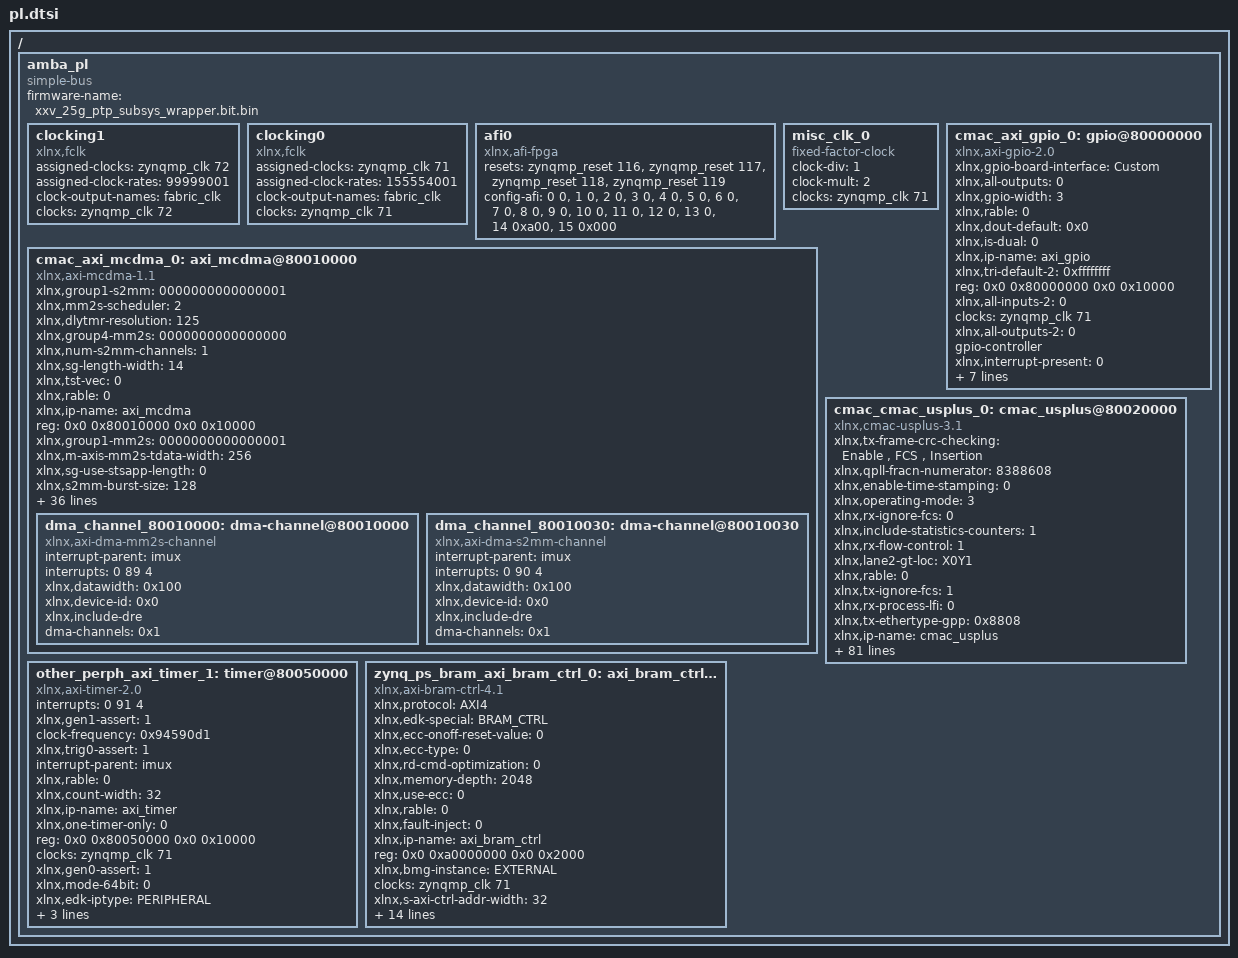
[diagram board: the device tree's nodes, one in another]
/ {
	amba_pl: amba_pl {
		ranges;
		compatible = "simple-bus";
		#address-cells = <2>;
		#size-cells = <2>;
		firmware-name = "xxv_25g_ptp_subsys_wrapper.bit.bin";
		clocking1: clocking1 {
			compatible = "xlnx,fclk";
			status = "okay";
			assigned-clocks = <&zynqmp_clk 72>;
			assigned-clock-rates = <99999001>;
			#clock-cells = <0>;
			clock-output-names = "fabric_clk";
			clocks = <&zynqmp_clk 72>;
		};
		clocking0: clocking0 {
			compatible = "xlnx,fclk";
			status = "okay";
			assigned-clocks = <&zynqmp_clk 71>;
			assigned-clock-rates = <155554001>;
			#clock-cells = <0>;
			clock-output-names = "fabric_clk";
			clocks = <&zynqmp_clk 71>;
		};
		afi0: afi0 {
			status = "okay";
			compatible = "xlnx,afi-fpga";
			resets = <&zynqmp_reset 116>, <&zynqmp_reset 117>, <&zynqmp_reset 118>, <&zynqmp_reset 119>;
			config-afi = < 0 0>, <1 0>, <2 0>, <3 0>, <4 0>, <5 0>, <6 0>, <7 0>, <8 0>, <9 0>, <10 0>, <11 0>, <12 0>, <13 0>, <14 0xa00>, <15 0x000>;
		};
		misc_clk_0: misc_clk_0 {
			clock-div = <1>;
			compatible = "fixed-factor-clock";
			clock-mult = <2>;
			clocks = <&zynqmp_clk 71>;
			#clock-cells = <0>;
		};
		cmac_axi_gpio_0: gpio@80000000 {
			xlnx,gpio-board-interface = "Custom";
			compatible = "xlnx,axi-gpio-2.0" , "xlnx,xps-gpio-1.00.a";
			xlnx,all-outputs = <0>;
			#gpio-cells = <2>;
			xlnx,gpio-width = <3>;
			xlnx,rable = <0>;
			xlnx,dout-default = <0x0>;
			xlnx,is-dual = <0>;
			xlnx,ip-name = "axi_gpio";
			xlnx,tri-default-2 = <0xffffffff>;
			reg = <0x0 0x80000000 0x0 0x10000>;
			xlnx,all-inputs-2 = <0>;
			clocks = <&zynqmp_clk 71>;
			xlnx,all-outputs-2 = <0>;
			gpio-controller;
			xlnx,interrupt-present = <0>;
			xlnx,gpio2-board-interface = "Custom";
			xlnx,edk-iptype = "PERIPHERAL";
			xlnx,dout-default-2 = <0x0>;
			status = "okay";
			xlnx,gpio2-width = <32>;
			clock-names = "s_axi_aclk";
			xlnx,tri-default = <0xffffffff>;
			xlnx,name = "cmac_axi_gpio_0";
			xlnx,all-inputs = <1>;
		};
		cmac_axi_mcdma_0: axi_mcdma@80010000 {
			xlnx,group1-s2mm = <0000000000000001>;
			xlnx,mm2s-scheduler = <2>;
			xlnx,dlytmr-resolution = <125>;
			xlnx,group4-mm2s = <0000000000000000>;
			xlnx,num-s2mm-channels = <1>;
			xlnx,sg-length-width = <14>;
			xlnx,tst-vec = <0>;
			xlnx,rable = <0>;
			xlnx,ip-name = "axi_mcdma";
			reg = <0x0 0x80010000 0x0 0x10000>;
			xlnx,group1-mm2s = <0000000000000001>;
			xlnx,m-axis-mm2s-tdata-width = <256>;
			xlnx,sg-use-stsapp-length = <0>;
			xlnx,s2mm-burst-size = <128>;
			xlnx,num-mm2s-channels = <1>;
			xlnx,group6-s2mm = <0000000000000000>;
			xlnx,enable-single-intr = <0>;
			interrupt-names = "mm2s_ch1_introut" , "s2mm_ch1_introut";
			xlnx,enable-multi-intr = <1>;
			compatible = "xlnx,axi-mcdma-1.1" , "xlnx,axi-mcdma-1.00.a";
			xlnx,group3-s2mm = <0000000000000000>;
			xlnx,mm2s-burst-size = <128>;
			interrupt-parent = <&imux>;
			xlnx,group6-mm2s = <0000000000000000>;
			xlnx,include-s2mm-dre = <1>;
			xlnx,group3-mm2s = <0000000000000000>;
			xlnx,m-axi-s2mm-data-width = <256>;
			status = "okay";
			xlnx,include-mm2s-dre = <1>;
			xlnx,name = "cmac_axi_mcdma_0";
			interrupts = < 0 89 4 0 90 4 >;
			xlnx,m-axi-mm2s-data-width = <256>;
			xlnx,group5-s2mm = <0000000000000000>;
			xlnx,include-s2mm-sf = <1>;
			xlnx,addr-width = <32>;
			xlnx,include-s2mm = <1>;
			xlnx,single-interface = <0>;
			clocks = <&misc_clk_0>, <&misc_clk_0>, <&zynqmp_clk 71>, <&zynqmp_clk 71>;
			xlnx,s-axis-s2mm-tdata-width = <256>;
			xlnx,addrwidth = /bits/ 8 <0x20>;
			xlnx,group2-s2mm = <0000000000000000>;
			xlnx,include-dre;
			xlnx,edk-iptype = "PERIPHERAL";
			xlnx,group5-mm2s = <0000000000000000>;
			xlnx,include-mm2s-sf = <1>;
			clock-names = "m_axi_mm2s_aclk" , "m_axi_s2mm_aclk" , "m_axi_sg_aclk" , "s_axi_lite_aclk";
			xlnx,include-mm2s = <1>;
			xlnx,s2mm-data-width = <0x100>;
			xlnx,group2-mm2s = <0000000000000000>;
			xlnx,prmry-is-aclk-async = <1>;
			#dma-cells = <1>;
			xlnx,sg-include-stscntrl-strm = <0>;
			xlnx,mm2s-data-width = <0x100>;
			xlnx,group4-s2mm = <0000000000000000>;
			dma_channel_80010000: dma-channel@80010000 {
				interrupt-parent = <&imux>;
				interrupts = < 0 89 4 >;
				xlnx,datawidth = <0x100>;
				xlnx,device-id = <0x0>;
				compatible = "xlnx,axi-dma-mm2s-channel";
				xlnx,include-dre;
				dma-channels = <0x1>;
			};
			dma_channel_80010030: dma-channel@80010030 {
				interrupt-parent = <&imux>;
				interrupts = < 0 90 4 >;
				xlnx,datawidth = <0x100>;
				xlnx,device-id = <0x0>;
				compatible = "xlnx,axi-dma-s2mm-channel";
				xlnx,include-dre;
				dma-channels = <0x1>;
			};
		};
		cmac_cmac_usplus_0: cmac_usplus@80020000 {
			xlnx,tx-frame-crc-checking = "Enable , FCS , Insertion";
			xlnx,qpll-fracn-numerator = <8388608>;
			xlnx,enable-time-stamping = <0>;
			xlnx,operating-mode = <3>;
			xlnx,rx-ignore-fcs = <0>;
			xlnx,include-statistics-counters = <1>;
			xlnx,rx-flow-control = <1>;
			xlnx,lane2-gt-loc = "X0Y1";
			xlnx,rable = <0>;
			xlnx,tx-ignore-fcs = <1>;
			xlnx,rx-process-lfi = <0>;
			xlnx,tx-ethertype-gpp = <0x8808>;
			xlnx,ip-name = "cmac_usplus";
			reg = <0x0 0x80020000 0x0 0x10000>;
			xlnx,enable-axis = <0>;
			xlnx,add-gt-cnrl-sts-ports = <0>;
			xlnx,include-auto-neg-lt-logic = <0>;
			xlnx,line-rate = <0x1896402>;
			xlnx,gt-group-select = <0>;
			xlnx,rx-delete-fcs = <1>;
			xlnx,enable-axi-interface = <1>;
			xlnx,lane1-gt-loc = "X0Y0";
			xlnx,rx-forward-control-frames = <0>;
			xlnx,diffclk-board-interface = "Custom";
			xlnx,fast-sim-mode = <0>;
			xlnx,tx-sa-ppp = <0x0>;
			xlnx,tx-da-gpp = <0x180 0xc2000001>;
			compatible = "xlnx,cmac-usplus-3.1";
			xlnx,gt-type = "GTY";
			xlnx,rx-opcode-gpp = <0x1>;
			xlnx,rx-pause-sa = <0x0>;
			xlnx,tx-opcode-gpp = <0x1>;
			xlnx,exdes-axi4lite-interface = <0>;
			xlnx,tx-ptp-vlane-adjust-mode = <0>;
			xlnx,rx-check-preamble = <0>;
			xlnx,rx-etype-gpp = <0x8808>;
			xlnx,include-shared-logic = <2>;
			xlnx,rx-pause-da-mcast = <0x180 0xc2000001>;
			xlnx,family-chk = "zynquplus";
			xlnx,rx-max-packet-len = <9600>;
			status = "okay";
			xlnx,use-board-flow;
			xlnx,pll-type = "QPLL0";
			xlnx,rs-fec-transcode-bypass = <0>;
			xlnx,tx-fcs-ins-enable = <1>;
			xlnx,tx-ethertype-ppp = <0x8808>;
			xlnx,tx-lane0-vlm-bip7-override = <0>;
			xlnx,rx-opcode-min-gcp = <0x0>;
			xlnx,name = "cmac_cmac_usplus_0";
			xlnx,rx-opcode-max-gcp = <0xffff>;
			xlnx,rx-pause-da-ucast = <0x0>;
			xlnx,clocking-mode = "Asynchronous";
			xlnx,is-board-project = <1>;
			xlnx,enable-pipeline-reg = <0>;
			xlnx,ptp-transpclk-mode = <0>;
			xlnx,rx-etype-gcp = <0x8808>;
			xlnx,tx-flow-control = <1>;
			xlnx,gt-ref-clk-freq = <0x9502f90>;
			xlnx,update-lt-coeff = <0>;
			xlnx,gt-rx-buffer-bypass = <0>;
			xlnx,include-an-lt-tx-trainer = <0>;
			xlnx,num-lanes = <4>;
			clocks = <&zynqmp_clk 72>, <&zynqmp_clk 71>, <&misc_clk_0>, <&zynqmp_clk 71>;
			xlnx,cmac-caui4-mode = <1>;
			xlnx,gt-location = <1>;
			xlnx,rx-check-ack = <0>;
			xlnx,tx-da-ppp = <0x180 0xc2000001>;
			xlnx,edk-iptype = "PERIPHERAL";
			xlnx,rx-min-packet-len = <64>;
			xlnx,user-interface = "AXIS";
			xlnx,ins-loss-nyq = <12>;
			xlnx,rx-opcode-ppp = <0x101>;
			clock-names = "drp_clk" , "init_clk" , "rx_clk" , "s_axi_aclk";
			xlnx,rx-check-sfd = <0>;
			xlnx,tx-opcode-ppp = <0x101>;
			xlnx,ethernet-board-interface = "Custom";
			xlnx,tx-ptp-latency-adjust = <0>;
			xlnx,rx-etype-ppp = <0x8808>;
			xlnx,gt-drp-clk = <100>;
			xlnx,cmac-core-select = "CMACE4_X0Y0";
			xlnx,lane4-gt-loc = "X0Y3";
			xlnx,rs-fec-core-sel = "CMACE4_X0Y0";
			xlnx,statistics-regs-type = <0>;
			xlnx,tx-sa-gpp = <0x0>;
			xlnx,include-rs-fec = <1>;
			xlnx,rx-opcode-min-pcp = <0x0>;
			xlnx,tx-ptp-1step-enable = <0>;
			xlnx,tx-ipg-value = <12>;
			xlnx,rx-opcode-max-pcp = <0xffff>;
			xlnx,lane3-gt-loc = "X0Y2";
			xlnx,rx-etype-pcp = <0x8808>;
			xlnx,rx-eq-mode = "AUTO";
			xlnx,tx-otn-interface = <0>;
			xlnx,rx-frame-crc-checking = "Enable , FCS , Stripping";
			xlnx,rx-gt-buffer = <1>;
		};
		other_perph_axi_timer_1: timer@80050000 {
			interrupts = < 0 91 4 >;
			compatible = "xlnx,axi-timer-2.0" , "xlnx,xps-timer-1.00.a";
			xlnx,gen1-assert = <1>;
			clock-frequency = <0x94590d1>;
			xlnx,trig0-assert = <1>;
			interrupt-parent = <&imux>;
			xlnx,rable = <0>;
			xlnx,count-width = <32>;
			xlnx,ip-name = "axi_timer";
			xlnx,one-timer-only = <0>;
			reg = <0x0 0x80050000 0x0 0x10000>;
			clocks = <&zynqmp_clk 71>;
			xlnx,gen0-assert = <1>;
			xlnx,mode-64bit = <0>;
			xlnx,edk-iptype = "PERIPHERAL";
			status = "okay";
			xlnx,trig1-assert = <1>;
			clock-names = "s_axi_aclk";
			xlnx,enable-timer2 = <1>;
			interrupt-names = "interrupt";
			xlnx,name = "other_perph_axi_timer_1";
		};
		zynq_ps_bram_axi_bram_ctrl_0: axi_bram_ctrl@a0000000 {
			xlnx,protocol = "AXI4";
			xlnx,edk-special = "BRAM_CTRL";
			compatible = "xlnx,axi-bram-ctrl-4.1";
			xlnx,ecc-onoff-reset-value = <0>;
			xlnx,ecc-type = <0>;
			xlnx,rd-cmd-optimization = <0>;
			xlnx,memory-depth = <2048>;
			xlnx,use-ecc = <0>;
			xlnx,rable = <0>;
			xlnx,fault-inject = <0>;
			xlnx,ip-name = "axi_bram_ctrl";
			reg = <0x0 0xa0000000 0x0 0x2000>;
			xlnx,bmg-instance = "EXTERNAL";
			clocks = <&zynqmp_clk 71>;
			xlnx,s-axi-ctrl-addr-width = <32>;
			xlnx,read-latency = <1>;
			xlnx,id-width = <0>;
			xlnx,s-axi-supports-narrow-burst = <1>;
			xlnx,supports-narrow-burst = <1>;
			xlnx,single-port-bram = <0>;
			xlnx,ecc = <0>;
			xlnx,edk-iptype = "PERIPHERAL";
			status = "okay";
			clock-names = "s_axi_aclk";
			xlnx,data-width = <32>;
			xlnx,bram-addr-width = <11>;
			xlnx,bram-inst-mode = "EXTERNAL";
			xlnx,s-axi-ctrl-data-width = <32>;
			xlnx,mem-depth = <2048>;
			xlnx,s-axi-id-width = <1>;
			xlnx,name = "zynq_ps_bram_axi_bram_ctrl_0";
		};
	};
};
